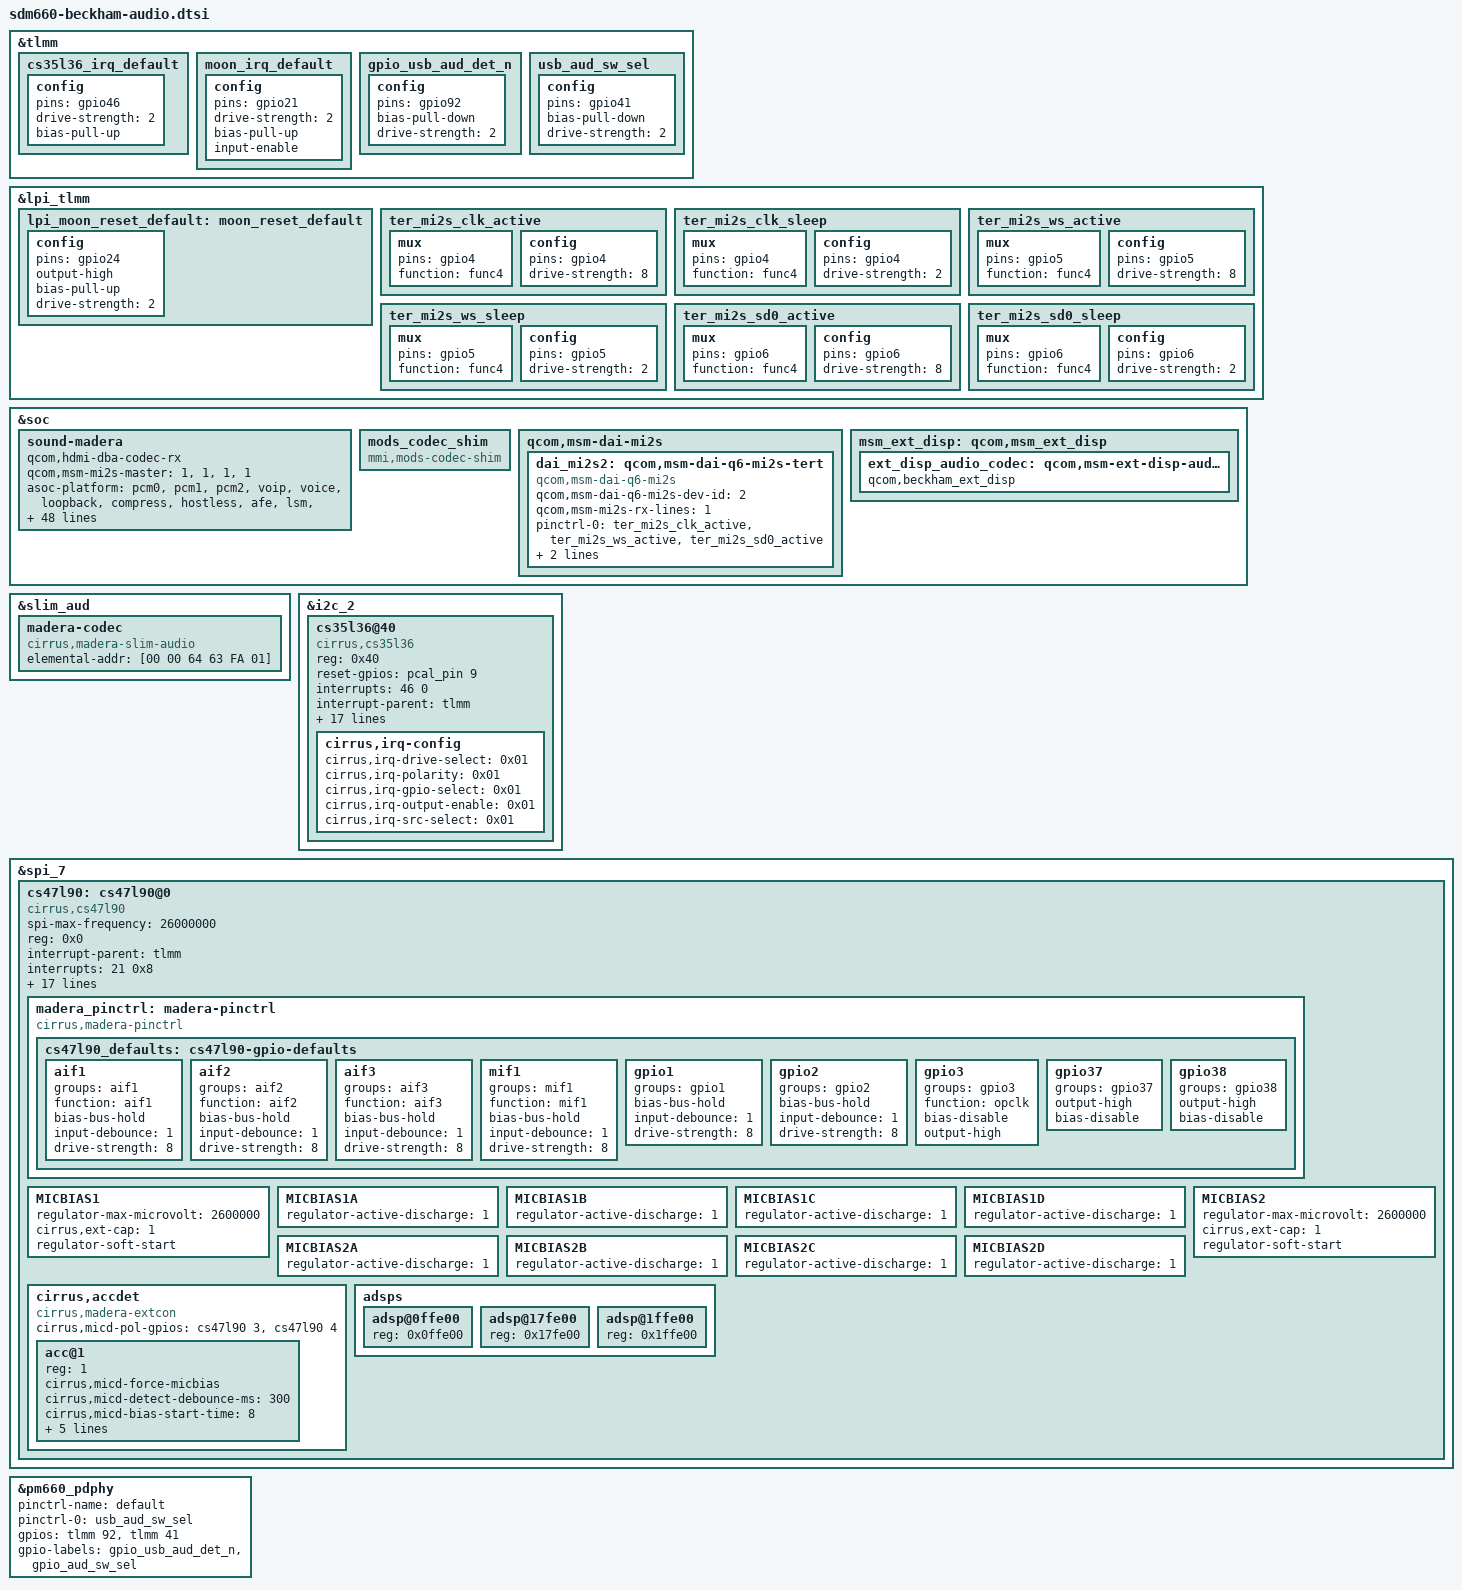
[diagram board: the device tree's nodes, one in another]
/* Copyright (c) 2017, Motorola Mobility Inc. All rights reserved.
 *
 * This program is free software; you can redistribute it and/or modify
 * it under the terms of the GNU General Public License version 2 and
 * only version 2 as published by the Free Software Foundation.
 *
 * This program is distributed in the hope that it will be useful,
 * but WITHOUT ANY WARRANTY; without even the implied warranty of
 * MERCHANTABILITY or FITNESS FOR A PARTICULAR PURPOSE.  See the
 * GNU General Public License for more details.
 */

#include "sdm660-moto-audio.dtsi"

&tlmm {
	/delete-node/ mdss_dp_usbplug_cc_active;
	/delete-node/ mdss_dp_usbplug_cc_suspend;
	/delete-node/ cs35l35_reset_default;
	/delete-node/ cs35l35_irq_default;
	/delete-node/ marley_irq_default;
	/delete-node/ marley_reset_default;

	cs35l36_irq_default: cs35l36_irq_default {
		config {
			pins = "gpio46";
			drive-strength = <2>;
			bias-pull-up;
		};
	};

	moon_irq_default: moon_irq_default {
		config {
			pins = "gpio21";
			drive-strength = <2>;
			bias-pull-up;
			input-enable;
		};
	};

	gpio_usb_aud_det_n: gpio_usb_aud_det_n {
		config {
			pins = "gpio92";
			bias-pull-down;
			drive-strength = <2>;
		};
	};
	usb_aud_sw_sel: usb_aud_sw_sel {
		config {
			pins = "gpio41";
			bias-pull-down;
			drive-strength = <2>;
		};
	};
};

&lpi_tlmm {
	lpi_moon_reset_default: moon_reset_default {
		config {
			pins = "gpio24";
			output-high;
			bias-pull-up;
			drive-strength = <2>;
		};
	};

	ter_mi2s_clk_active: ter_mi2s_clk_active {
		mux {
			pins = "gpio4";
			function = "func4";
		};

		config {
			pins = "gpio4";
			drive-strength = <8>;
		};
	};

	ter_mi2s_clk_sleep: ter_mi2s_clk_sleep {
		mux {
			pins = "gpio4";
			function = "func4";
		};

		config {
			pins = "gpio4";
			drive-strength = <2>;
		};
	};

	ter_mi2s_ws_active: ter_mi2s_ws_active {
		mux {
			pins = "gpio5";
			function = "func4";
		};

		config {
			pins = "gpio5";
			drive-strength = <8>;
		};
	};

	ter_mi2s_ws_sleep: ter_mi2s_ws_sleep {
		mux {
			pins = "gpio5";
			function = "func4";
		};

		config {
			pins = "gpio5";
			drive-strength = <2>;
		};
	};
	ter_mi2s_sd0_active: ter_mi2s_sd0_active {
		mux {
			pins = "gpio6";
			function = "func4";
		};

		config {
			pins = "gpio6";
			drive-strength = <8>;
		};
	};

	ter_mi2s_sd0_sleep: ter_mi2s_sd0_sleep {
		mux {
			pins = "gpio6";
			function = "func4";
		};

		config {
			pins = "gpio6";
			drive-strength = <2>;
		};
	};
};

&soc {
	/delete-node/ audio_ext_clk;

	sound-madera {
		/delete-property/ asoc-platform;
		/delete-property/ asoc-platform-names;
		/delete-property/ qcom,audio-routing;
		qcom,hdmi-dba-codec-rx;
		qcom,msm-mi2s-master = <1>, <1>, <1>, <1>;

		asoc-platform = <&pcm0>, <&pcm1>, <&pcm2>, <&voip>, <&voice>,
				<&loopback>, <&compress>, <&hostless>,
				<&afe>, <&lsm>, <&routing>, <&cpe>, <&compr>,
				<&pcm_noirq>, <&cs47l90>, <&pcm_noirq>;
		asoc-platform-names = "msm-pcm-dsp.0", "msm-pcm-dsp.1",
				"msm-pcm-dsp.2", "msm-voip-dsp",
				"msm-pcm-voice", "msm-pcm-loopback",
				"msm-compress-dsp", "msm-pcm-hostless",
				"msm-pcm-afe", "msm-lsm-client",
				"msm-pcm-routing", "msm-cpe-lsm",
				"msm-compr-dsp", "msm-pcm-dsp-noirq",
				"cs47l90-codec", "msm-pcm-dsp-noirq";
		asoc-cpu = <&dai_mi2s2>,
				<&sb_0_rx>, <&sb_0_tx>, <&sb_1_rx>, <&sb_1_tx>,
				<&sb_2_rx>, <&sb_2_tx>, <&sb_3_rx>, <&sb_3_tx>,
				<&sb_4_rx>, <&sb_4_tx>, <&sb_5_tx>,
				<&afe_pcm_rx>, <&afe_pcm_tx>, <&afe_proxy_rx>,
				<&afe_proxy_tx>, <&incall_record_rx>,
				<&incall_record_tx>, <&incall_music_rx>,
				<&incall_music_2_rx>, <&sb_5_rx>,
				<&usb_audio_rx>, <&usb_audio_tx>, <&sb_6_rx>,
				<&sb_7_rx>, <&sb_7_tx>, <&sb_8_tx>,
				<&dai_pri_tdm_rx_0>, <&dai_pri_tdm_tx_0>,
				<&dai_sec_tdm_rx_0>, <&dai_sec_tdm_tx_0>,
				<&dai_tert_tdm_rx_0>, <&dai_tert_tdm_tx_0>,
				<&dai_quat_tdm_rx_0>, <&dai_quat_tdm_tx_0>,
				<&proxy_rx>, <&proxy_tx>;
		asoc-cpu-names = "msm-dai-q6-mi2s.2",
				"msm-dai-q6-dev.16384", "msm-dai-q6-dev.16385",
				"msm-dai-q6-dev.16386", "msm-dai-q6-dev.16387",
				"msm-dai-q6-dev.16388", "msm-dai-q6-dev.16389",
				"msm-dai-q6-dev.16390", "msm-dai-q6-dev.16391",
				"msm-dai-q6-dev.16392", "msm-dai-q6-dev.16393",
				"msm-dai-q6-dev.16395", "msm-dai-q6-dev.224",
				"msm-dai-q6-dev.225", "msm-dai-q6-dev.241",
				"msm-dai-q6-dev.240", "msm-dai-q6-dev.32771",
				"msm-dai-q6-dev.32772", "msm-dai-q6-dev.32773",
				"msm-dai-q6-dev.32770", "msm-dai-q6-dev.16394",
				"msm-dai-q6-dev.28672", "msm-dai-q6-dev.28673",
				"msm-dai-q6-dev.16396", "msm-dai-q6-dev.16398",
				"msm-dai-q6-dev.16399", "msm-dai-q6-dev.16401",
				"msm-dai-q6-tdm.36864", "msm-dai-q6-tdm.36865",
				"msm-dai-q6-tdm.36880", "msm-dai-q6-tdm.36881",
				"msm-dai-q6-tdm.36896", "msm-dai-q6-tdm.36897",
				"msm-dai-q6-tdm.36912", "msm-dai-q6-tdm.36913",
				"msm-dai-q6-dev.8194", "msm-dai-q6-dev.8195";
		qcom,audio-routing =
			"IN2ALN", "MICBIAS2A",
			"IN2ALP", "MICBIAS2A",
			"IN1ALN", "MICBIAS2B",
			"IN1ALP", "MICBIAS2B",
			"IN2RN",  "MICBIAS2C",
			"IN2RP",  "MICBIAS2C",
			"IN1ARN", "MICBIAS2D",
			"IN1ARP", "MICBIAS2D",
			"IN1BRN", "MICBIAS1A",
			"IN1BRP", "MICBIAS1B";
	};

	mods_codec_shim {
		compatible = "mmi,mods-codec-shim";
	};

	qcom,msm-dai-mi2s {
		dai_mi2s2: qcom,msm-dai-q6-mi2s-tert {
			compatible = "qcom,msm-dai-q6-mi2s";
			status = "ok";
			qcom,msm-dai-q6-mi2s-dev-id = <2>;
			qcom,msm-mi2s-rx-lines = <1>;
			pinctrl-names = "default","idle";
			pinctrl-0 = <&ter_mi2s_clk_active &ter_mi2s_ws_active
				&ter_mi2s_sd0_active>;
			pinctrl-1 = <&ter_mi2s_clk_sleep &ter_mi2s_ws_sleep
				&ter_mi2s_sd0_sleep>;
		};
	};

	/delete-node/ qcom,msm-ext-disp;
	/delete-node/sound-tavil;

	msm_ext_disp: qcom,msm_ext_disp {
		ext_disp_audio_codec: qcom,msm-ext-disp-audio-codec-rx {
			qcom,beckham_ext_disp;
		};
	};
};

&slim_aud {
	/delete-node/ tasha_codec;
	/delete-node/ tavil_codec;
	madera-codec {
		compatible = "cirrus,madera-slim-audio";
		elemental-addr = [00 00 64 63 FA 01];
	};
};

&i2c_2 {
	/delete-node/ cs35l35@40;
	cs35l36@40 {
		status = "ok";
		compatible = "cirrus,cs35l36";
		reg = <0x40>;
		reset-gpios = <&pcal_pin 9 0>;
		interrupts = <46 0>;
		interrupt-parent = <&tlmm>;
		VA-supply = <&dummy_vreg>;
		VP-supply = <&dummy_vreg>;

		pinctrl-names = "default";
		pinctrl-0 = <&cs35l36_irq_default>;

		cirrus,left-channel-amp;
		cirrus,boost-ind-nanohenry = <1000>; /* 1uH */
		cirrus,boost-ctl-millivolt = <10000>;
		cirrus,boost-peak-milliamp = <4500>;
		cirrus,amp-gain-zc;
		cirrus,weak-fet-delay = <0x04>;
		cirrus,weak-fet-thld = <0x01>;
		cirrus,temp-warn-threshold = <0x01>;
		cirrus,vpr-en = <1>;
		cirrus,vpr-thrld = <12>;
		cirrus,vpr-atk-vol = <3>;
		cirrus,vpr-atk-rate = <2>;
		cirrus,vpr-wait = <0>;
		cirrus,vpr-rel-rate = <3>;

		cirrus,irq-config {
			cirrus,irq-drive-select = <0x01>;
			cirrus,irq-polarity = <0x01>;
			cirrus,irq-gpio-select = <0x01>;
			cirrus,irq-output-enable = <0x01>;
			cirrus,irq-src-select = <0x01>;
		};
	};
};

&spi_7 {
	/delete-node/ cs47l35@0;
	cs47l90: cs47l90@0 {
		compatible = "cirrus,cs47l90";
		spi-max-frequency = <26000000>;
		reg = <0x0>;
		interrupt-parent = <&tlmm>;
		interrupts = <21 0x8>;
		interrupt-controller;
		#interrupt-cells = <2>;
		reset-gpios = <&lpi_tlmm 24 0>;
		pinctrl-names = "probe", "active";
		pinctrl-0 = <&moon_irq_default &lpi_moon_reset_default>;
		pinctrl-1 = <&moon_irq_default &lpi_moon_reset_default &cs47l90_defaults>;

		AVDD-supply = <&pm660_l13>;
		DBVDD1-supply = <&pm660_l13>;
		DBVDD2-supply = <&pm660_l13>;
		CPVDD-supply = <&pm660_l13>;
		CPVDD1-supply = <&pm660_l13>;
		CPVDD2-supply = <&pm660_l14>;
		DCVDD-supply = <&pm660_l13>;
		SPKVDD-supply = <&dummy_vreg>;

		gpio-controller;
		#gpio-cells = <2>;
		cirrus,inmode = < 0 0 0 0 0 0 0 0 >;
		cirrus,out-mono = <0 0 0 0 0 0>;

		madera_pinctrl: madera-pinctrl {
				compatible = "cirrus,madera-pinctrl";
				cs47l90_defaults: cs47l90-gpio-defaults {
					aif1 {
						groups = "aif1";
						function = "aif1";
						bias-bus-hold;
						input-debounce = <1>;
						drive-strength = <8>;
					};

					aif2 {
						groups = "aif2";
						function = "aif2";
						bias-bus-hold;
						input-debounce = <1>;
						drive-strength = <8>;
					};

					aif3 {
						groups = "aif3";
						function = "aif3";
						bias-bus-hold;
						input-debounce = <1>;
						drive-strength = <8>;
					};

					mif1 {
						groups = "mif1";
						function = "mif1";
						bias-bus-hold;
						input-debounce = <1>;
						drive-strength = <8>;
					};

					gpio1 {
						groups = "gpio1";
						bias-bus-hold;
						input-debounce = <1>;
						drive-strength = <8>;
					};


					gpio2 {
						groups = "gpio2";
						bias-bus-hold;
						input-debounce = <1>;
						drive-strength = <8>;
					};

					gpio3 {
						groups = "gpio3";
						function = "opclk";
						bias-disable;
						output-high;
					};

					gpio37 {
						groups = "gpio37";
						output-high;
						bias-disable;
					};

					gpio38 {
						groups = "gpio38";
						output-high;
						bias-disable;
					};
				};
		};	

		MICBIAS1 {
			regulator-max-microvolt = <2600000>;
			cirrus,ext-cap = <1>;
			regulator-soft-start;
		};

		MICBIAS1A {
			regulator-active-discharge = <1>;
		};

		MICBIAS1B {
			regulator-active-discharge = <1>;
		};

		MICBIAS1C {
			regulator-active-discharge = <1>;
		};

		MICBIAS1D {
			regulator-active-discharge = <1>;
		};

		MICBIAS2 {
			regulator-max-microvolt = <2600000>;
			cirrus,ext-cap = <1>;
			regulator-soft-start;
		};

		MICBIAS2A {
			regulator-active-discharge = <1>;
		};

		MICBIAS2B {
			regulator-active-discharge = <1>;
		};

		MICBIAS2C {
			regulator-active-discharge = <1>;
		};

		MICBIAS2D {
			regulator-active-discharge = <1>;
		};

		cirrus,accdet {
			compatible = "cirrus,madera-extcon";
			#address-cells = <1>;
			#size-cells = <0>;

			cirrus,micd-pol-gpios = <&cs47l90 3 0>,
							<&cs47l90 4 0>;
			acc@1 {
				reg = <1>;

				cirrus,micd-force-micbias;
				cirrus,micd-detect-debounce-ms = <300>;
				cirrus,micd-bias-start-time = <8>;
				cirrus,micd-rate = <6>;
				cirrus,micd-dbtime = <0x1>;
				cirrus,micd-ranges = <
					70 0xE2		/* KEY_MEDIA */
					180 0x246	/* KEY_VOICECOMMAND */
					290 0x73	/* KEY_VOLUMEUP */
					680 0x72	/* KEY_VOLUMEDOWN */
				>;
				cirrus,micd-configs = <
					1 0 1 1 0
					0 1 0 0 1
				>;
			};
		};
		adsps {
			#address-cells = <1>;
			#size-cells = <0>;
			adsp@0ffe00 {
				reg = <0x0ffe00>;
			};
			adsp@17fe00 {
				reg = <0x17fe00>;
			};
			adsp@1ffe00 {
				reg = <0x1ffe00>;
			};
		};

	};
};

&pm660_pdphy {
	pinctrl-name = "default";
	pinctrl-0 = <&usb_aud_sw_sel>;

	gpios = <&tlmm 92 0>,  /* USB_AUD_DET_N, output-high */
		<&tlmm 41 0>;  /* USB_AUD_SW_SEL, output-low */

	gpio-labels = "gpio_usb_aud_det_n",
		"gpio_aud_sw_sel";
};
